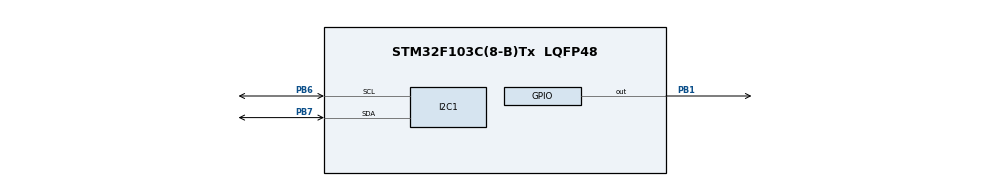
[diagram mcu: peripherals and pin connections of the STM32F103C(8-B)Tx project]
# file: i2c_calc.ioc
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FREERTOS.Tasks01=defaultTask,0,128,StartDefaultTask,Default,NULL
I2C1.OwnAddress=10
Mcu.Family=STM32F1
Mcu.Name=STM32F103C(8-B)Tx
Mcu.Package=LQFP48
NVIC.I2C1_ER_IRQn=true\:5\:0\:false\:false\:true\:true\:true
NVIC.I2C1_EV_IRQn=true\:5\:0\:false\:false\:true\:true\:true
NVIC.PriorityGroup=NVIC_PRIORITYGROUP_4
PA13.Mode=Serial_Wire
PA13.Signal=SYS_JTMS-SWDIO
PA14.Mode=Serial_Wire
PA14.Signal=SYS_JTCK-SWCLK
PB1.Signal=GPIO_Output
PB6.Mode=I2C
PB6.Signal=I2C1_SCL
PB7.Mode=I2C
PB7.Signal=I2C1_SDA
ProjectManager.HeapSize=0x200
ProjectManager.StackSize=0x400
ProjectManager.TargetToolchain=SW4STM32
RCC.APB1Freq_Value=8000000
RCC.APB2Freq_Value=8000000
VP_FREERTOS_VS_ENABLE.Mode=Enabled
board=i2c_calc

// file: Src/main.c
/**
  ******************************************************************************
  * File Name          : main.c
  * Description        : Main program body
  ******************************************************************************
  * This notice applies to any and all portions of this file
  * that are not between comment pairs USER CODE BEGIN and
  * USER CODE END. Other portions of this file, whether
  * inserted by the user or by software development tools
  * are owned by their respective copyright owners.
  *
  * Copyright (c) 2018 STMicroelectronics International N.V.
  * All rights reserved.
  *
  * Redistribution and use in source and binary forms, with or without
  * modification, are permitted, provided that the following conditions are met:
  *
  * 1. Redistribution of source code must retain the above copyright notice,
  *    this list of conditions and the following disclaimer.
  * 2. Redistributions in binary form must reproduce the above copyright notice,
  *    this list of conditions and the following disclaimer in the documentation
  *    and/or other materials provided with the distribution.
  * 3. Neither the name of STMicroelectronics nor the names of other
  *    contributors to this software may be used to endorse or promote products
  *    derived from this software without specific written permission.
  * 4. This software, including modifications and/or derivative works of this
  *    software, must execute solely and exclusively on microcontroller or
  *    microprocessor devices manufactured by or for STMicroelectronics.
  * 5. Redistribution and use of this software other than as permitted under
  *    this license is void and will automatically terminate your rights under
  *    this license.
  *
  * THIS SOFTWARE IS PROVIDED BY STMICROELECTRONICS AND CONTRIBUTORS "AS IS"
  * AND ANY EXPRESS, IMPLIED OR STATUTORY WARRANTIES, INCLUDING, BUT NOT
  * LIMITED TO, THE IMPLIED WARRANTIES OF MERCHANTABILITY, FITNESS FOR A
  * PARTICULAR PURPOSE AND NON-INFRINGEMENT OF THIRD PARTY INTELLECTUAL PROPERTY
  * RIGHTS ARE DISCLAIMED TO THE FULLEST EXTENT PERMITTED BY LAW. IN NO EVENT
  * SHALL STMICROELECTRONICS OR CONTRIBUTORS BE LIABLE FOR ANY DIRECT, INDIRECT,
  * INCIDENTAL, SPECIAL, EXEMPLARY, OR CONSEQUENTIAL DAMAGES (INCLUDING, BUT NOT
  * LIMITED TO, PROCUREMENT OF SUBSTITUTE GOODS OR SERVICES; LOSS OF USE, DATA,
  * OR PROFITS; OR BUSINESS INTERRUPTION) HOWEVER CAUSED AND ON ANY THEORY OF
  * LIABILITY, WHETHER IN CONTRACT, STRICT LIABILITY, OR TORT (INCLUDING
  * NEGLIGENCE OR OTHERWISE) ARISING IN ANY WAY OUT OF THE USE OF THIS SOFTWARE,
  * EVEN IF ADVISED OF THE POSSIBILITY OF SUCH DAMAGE.
  *
  ******************************************************************************
  */

#include "main.h"
#include "stm32f1xx_hal.h"
#include "cmsis_os.h"
#include "i2c.h"
#include "gpio.h"

/* USER CODE BEGIN PV */
/* Private variables ---------------------------------------------------------*/

/* USER CODE END PV */

void SystemClock_Config(void);
void MX_FREERTOS_Init(void);

/* USER CODE BEGIN PFP */
/* Private function prototypes -----------------------------------------------*/

/* USER CODE END PFP */

int main(void)
{

  /* MCU Configuration----------------------------------------------------------*/

  /* Reset of all peripherals, Initializes the Flash interface and the Systick. */
  HAL_Init();

  /* Configure the system clock */
  SystemClock_Config();

  /* Initialize all configured peripherals */
  MX_GPIO_Init();
  MX_I2C1_Init();

  /* Call init function for freertos objects (in freertos.c) */
  MX_FREERTOS_Init();

  /* Start scheduler */
  osKernelStart();

  /* We should never get here as control is now taken by the scheduler */

  /* Infinite loop */
  while (1)
  {

  }

}

/** System Clock Configuration
*/
void SystemClock_Config(void)
{

  RCC_OscInitTypeDef RCC_OscInitStruct;
  RCC_ClkInitTypeDef RCC_ClkInitStruct;

    /**Initializes the CPU, AHB and APB busses clocks
    */
  RCC_OscInitStruct.OscillatorType = RCC_OSCILLATORTYPE_HSI;
  RCC_OscInitStruct.HSIState = RCC_HSI_ON;
  RCC_OscInitStruct.HSICalibrationValue = 16;
  RCC_OscInitStruct.PLL.PLLState = RCC_PLL_NONE;
  if (HAL_RCC_OscConfig(&RCC_OscInitStruct) != HAL_OK)
  {
    _Error_Handler(__FILE__, __LINE__);
  }

    /**Initializes the CPU, AHB and APB busses clocks
    */
  RCC_ClkInitStruct.ClockType = RCC_CLOCKTYPE_HCLK|RCC_CLOCKTYPE_SYSCLK
                              |RCC_CLOCKTYPE_PCLK1|RCC_CLOCKTYPE_PCLK2;
  RCC_ClkInitStruct.SYSCLKSource = RCC_SYSCLKSOURCE_HSI;
  RCC_ClkInitStruct.AHBCLKDivider = RCC_SYSCLK_DIV1;
  RCC_ClkInitStruct.APB1CLKDivider = RCC_HCLK_DIV1;
  RCC_ClkInitStruct.APB2CLKDivider = RCC_HCLK_DIV1;

  if (HAL_RCC_ClockConfig(&RCC_ClkInitStruct, FLASH_LATENCY_0) != HAL_OK)
  {
    _Error_Handler(__FILE__, __LINE__);
  }

    /**Configure the Systick interrupt time
    */
  HAL_SYSTICK_Config(HAL_RCC_GetHCLKFreq()/1000);

    /**Configure the Systick
    */
  HAL_SYSTICK_CLKSourceConfig(SYSTICK_CLKSOURCE_HCLK);

  /* SysTick_IRQn interrupt configuration */
  HAL_NVIC_SetPriority(SysTick_IRQn, 15, 0);
}

void _Error_Handler(char * file, int line)
{
  while(1)
  {
  }
}

/************************ (C) COPYRIGHT STMicroelectronics *****END OF FILE****/

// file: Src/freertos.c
/**
  ******************************************************************************
  * File Name          : freertos.c
  * Description        : Code for freertos applications
  ******************************************************************************
  * This notice applies to any and all portions of this file
  * that are not between comment pairs USER CODE BEGIN and
  * USER CODE END. Other portions of this file, whether
  * inserted by the user or by software development tools
  * are owned by their respective copyright owners.
  *
  * Copyright (c) 2018 STMicroelectronics International N.V.
  * All rights reserved.
  *
  * Redistribution and use in source and binary forms, with or without
  * modification, are permitted, provided that the following conditions are met:
  *
  * 1. Redistribution of source code must retain the above copyright notice,
  *    this list of conditions and the following disclaimer.
  * 2. Redistributions in binary form must reproduce the above copyright notice,
  *    this list of conditions and the following disclaimer in the documentation
  *    and/or other materials provided with the distribution.
  * 3. Neither the name of STMicroelectronics nor the names of other
  *    contributors to this software may be used to endorse or promote products
  *    derived from this software without specific written permission.
  * 4. This software, including modifications and/or derivative works of this
  *    software, must execute solely and exclusively on microcontroller or
  *    microprocessor devices manufactured by or for STMicroelectronics.
  * 5. Redistribution and use of this software other than as permitted under
  *    this license is void and will automatically terminate your rights under
  *    this license.
  *
  * THIS SOFTWARE IS PROVIDED BY STMICROELECTRONICS AND CONTRIBUTORS "AS IS"
  * AND ANY EXPRESS, IMPLIED OR STATUTORY WARRANTIES, INCLUDING, BUT NOT
  * LIMITED TO, THE IMPLIED WARRANTIES OF MERCHANTABILITY, FITNESS FOR A
  * PARTICULAR PURPOSE AND NON-INFRINGEMENT OF THIRD PARTY INTELLECTUAL PROPERTY
  * RIGHTS ARE DISCLAIMED TO THE FULLEST EXTENT PERMITTED BY LAW. IN NO EVENT
  * SHALL STMICROELECTRONICS OR CONTRIBUTORS BE LIABLE FOR ANY DIRECT, INDIRECT,
  * INCIDENTAL, SPECIAL, EXEMPLARY, OR CONSEQUENTIAL DAMAGES (INCLUDING, BUT NOT
  * LIMITED TO, PROCUREMENT OF SUBSTITUTE GOODS OR SERVICES; LOSS OF USE, DATA,
  * OR PROFITS; OR BUSINESS INTERRUPTION) HOWEVER CAUSED AND ON ANY THEORY OF
  * LIABILITY, WHETHER IN CONTRACT, STRICT LIABILITY, OR TORT (INCLUDING
  * NEGLIGENCE OR OTHERWISE) ARISING IN ANY WAY OUT OF THE USE OF THIS SOFTWARE,
  * EVEN IF ADVISED OF THE POSSIBILITY OF SUCH DAMAGE.
  *
  ******************************************************************************
  */

#include "FreeRTOS.h"
#include "task.h"
#include "cmsis_os.h"

/* USER CODE BEGIN Includes */
#include "i2c.h"
#include "stm32f1xx.h"
/* USER CODE END Includes */

osThreadId defaultTaskHandle;

/* USER CODE BEGIN Variables */
uint8_t rx[2];
uint8_t tx[2];
int dir;
int pos = 0;

#define DIR_READ 0
#define DIR_WRITE 1

/* USER CODE END Variables */

void StartDefaultTask(void const * argument);

void MX_FREERTOS_Init(void); /* (MISRA C 2004 rule 8.1) */

/* USER CODE BEGIN FunctionPrototypes */
void start_over();

/* USER CODE END FunctionPrototypes */

/* Hook prototypes */

/* Init FreeRTOS */

void MX_FREERTOS_Init(void) {

  /* Create the thread(s) */
  /* definition and creation of defaultTask */
  osThreadDef(defaultTask, StartDefaultTask, osPriorityNormal, 0, 128);
  defaultTaskHandle = osThreadCreate(osThread(defaultTask), NULL);

}

/* StartDefaultTask function */
void StartDefaultTask(void const * argument)
{

  /* USER CODE BEGIN StartDefaultTask */
	start_over();
	for(;;) {
		osDelay(500);
		HAL_GPIO_TogglePin(GPIOB, GPIO_PIN_1);
	}
  /* USER CODE END StartDefaultTask */
}

/* USER CODE BEGIN Application */
void start_over() {
	pos = 0;
	configASSERT(HAL_I2C_EnableListen_IT(&hi2c1) == HAL_OK);
}

char ret = 0;
void HAL_I2C_SlaveTxCpltCallback(I2C_HandleTypeDef *hi2c) {
	// transmit done
}

void HAL_I2C_SlaveRxCpltCallback(I2C_HandleTypeDef *hi2c) {
	pos++;

	//configASSERT(HAL_I2C_Slave_Sequential_Receive_IT(hi2c, rx, 1, I2C_LAST_FRAME) == HAL_OK);

	/*

	pos++;
	if(pos == 2) {
		return;
	}

	configASSERT(HAL_I2C_Slave_Sequential_Receive_IT(hi2c, rx + pos, 1, I2C_NEXT_FRAME) == HAL_OK);
	 */
}

void HAL_I2C_AddrCallback(I2C_HandleTypeDef *hi2c, uint8_t TransferDirection, uint16_t AddrMatchCode) {
	pos = 0;

	if(TransferDirection == I2C_DIRECTION_TRANSMIT) {
		configASSERT(HAL_I2C_Slave_Sequential_Receive_IT(hi2c, rx, 1, I2C_FIRST_FRAME) == HAL_OK);
	} else if(TransferDirection == I2C_DIRECTION_RECEIVE) {
		tx[0]++;
		int val = HAL_I2C_Slave_Sequential_Transmit_IT(hi2c, tx, 1, I2C_FIRST_AND_LAST_FRAME);
		configASSERT(val == HAL_OK);
	} else {
		asm("bkpt #1");
	}
}

void HAL_I2C_ListenCpltCallback(I2C_HandleTypeDef *hi2c) {
	configASSERT(HAL_I2C_EnableListen_IT(&hi2c1) == HAL_OK);
}

void HAL_I2C_ErrorCallback(I2C_HandleTypeDef *hi2c) {
	asm("bkpt #1");
	if(hi2c->ErrorCode != HAL_I2C_ERROR_AF) {
		//start_over();
	} else {
		asm("bkpt #1");
	}
}

void HAL_I2C_AbortCpltCallback(I2C_HandleTypeDef *hi2c) {
	asm("bkpt #1");
}

/* USER CODE END Application */

/************************ (C) COPYRIGHT STMicroelectronics *****END OF FILE****/
